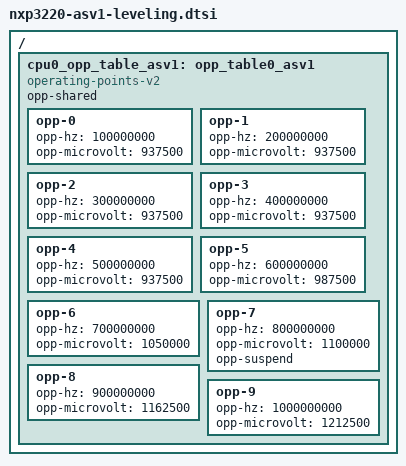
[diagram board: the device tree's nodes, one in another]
/{
	cpu0_opp_table_asv1: opp_table0_asv1 {
		compatible = "operating-points-v2";
		opp-shared;

		opp-0 {
			opp-hz = /bits/ 64 <100000000>;
			opp-microvolt = <937500>;
		};
		opp-1 {
			opp-hz = /bits/ 64 <200000000>;
			opp-microvolt = <937500>;
		};
		opp-2 {
			opp-hz = /bits/ 64 <300000000>;
			opp-microvolt = <937500>;
		};
		opp-3 {
			opp-hz = /bits/ 64 <400000000>;
			opp-microvolt = <937500>;
		};
		opp-4 {
			opp-hz = /bits/ 64 <500000000>;
			opp-microvolt = <937500>;
		};
		opp-5 {
			opp-hz = /bits/ 64 <600000000>;
			opp-microvolt = <987500>;
		};
		opp-6 {
			opp-hz = /bits/ 64 <700000000>;
			opp-microvolt = <1050000>;
		};
		opp-7 {
			opp-hz = /bits/ 64 <800000000>;
			opp-microvolt = <1100000>;
			opp-suspend;
		};
		opp-8 {
			opp-hz = /bits/ 64 <900000000>;
			opp-microvolt = <1162500>;
		};
		opp-9 {
			opp-hz = /bits/ 64 <1000000000>;
			opp-microvolt = <1212500>;
		};
	};

};
